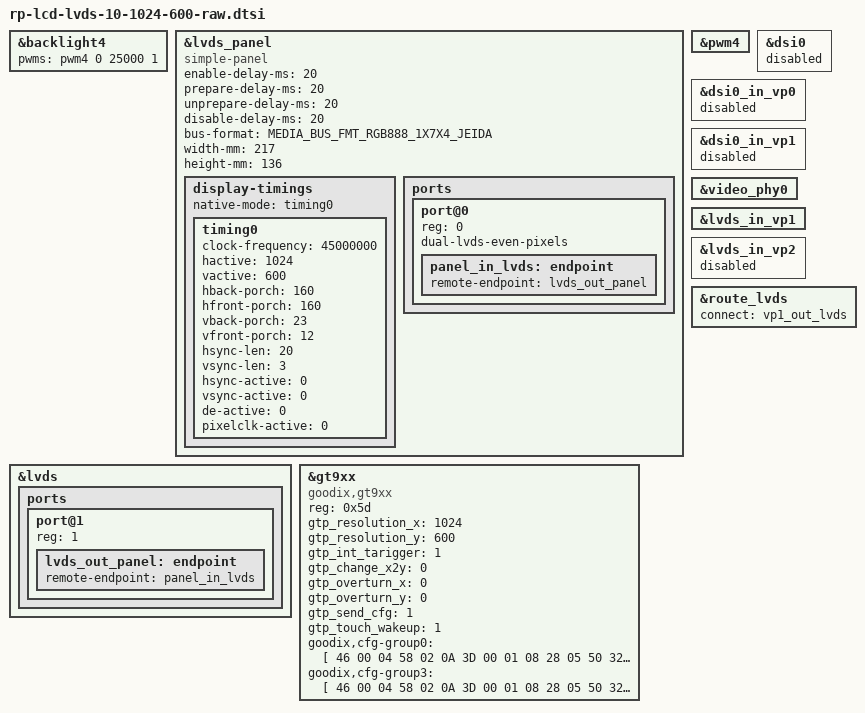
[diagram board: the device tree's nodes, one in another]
#include <dt-bindings/display/media-bus-format.h>
#include "rp-lcd-hdmi.dtsi"

&backlight4{
		pwms = <&pwm4 0 25000 1>;   /** pwm polarity of raw lvds screen is inverse */
};

&lvds_panel {
	status = "okay";
	compatible = "simple-panel";
	enable-delay-ms = <20>;
	prepare-delay-ms = <20>;
	unprepare-delay-ms = <20>;
	disable-delay-ms = <20>;
	bus-format = <MEDIA_BUS_FMT_RGB888_1X7X4_JEIDA>;
	width-mm = <217>;
	height-mm = <136>;
		
		/*
		 * power-supply = <>;
		 * reset-gpios = <>;
		 *
		 * lcd reset pin and power supply
		 * please refer to ***-lcd-gpio.dtsi
		 * that included in main dts.
		 */
		
	display-timings {
		native-mode = <&timing0>;

		timing0: timing0 {
			clock-frequency = <45000000>;
			hactive = <1024>;
			vactive = <600>;
			hback-porch = <160>;
			hfront-porch = <160>;
			vback-porch = <23>;
			vfront-porch = <12>;
			hsync-len = <20>;
			vsync-len = <3>;
			hsync-active = <0>;
			vsync-active = <0>;
			de-active = <0>;
			pixelclk-active = <0>;
		};
	};

	ports {
		#address-cells = <1>;
		#size-cells = <0>;

		port@0 {
			reg = <0>;
			dual-lvds-even-pixels;
			panel_in_lvds: endpoint {
				remote-endpoint = <&lvds_out_panel>;
			};
		};
	};
};

&lvds {
	status = "okay";
	ports {
		port@1 {
			reg = <1>;

			lvds_out_panel: endpoint {
				remote-endpoint = <&panel_in_lvds>;
			};
		};
	};
};





&pwm4 {
	status = "okay";
};

&dsi0 {
	status = "disabled";
};

&dsi0_in_vp0 {
	status = "disabled";
};

&dsi0_in_vp1 {
	status = "disabled";
};

&video_phy0 {
	status = "okay";
};

&lvds_in_vp1 {
	status = "okay";
};

&lvds_in_vp2 {
	status = "disabled";
};

&route_lvds {
	status = "okay";
	connect = <&vp1_out_lvds>;
};


	
&gt9xx {
        status = "okay";
        compatible = "goodix,gt9xx";
        reg = <0x5d>;
        gtp_resolution_x = <1024>;
        gtp_resolution_y = <600>;
        gtp_int_tarigger = <1>;
        gtp_change_x2y = <0>;
        gtp_overturn_x = <0>;
        gtp_overturn_y = <0>;
        gtp_send_cfg = <1>;
        gtp_touch_wakeup = <1>;

		/**
		 * goodix_rst_gpio = <>;
		 * goodix_irq_gpio = <>;
		 *
		 * touch panel interrupt and reset pin
		 * please refer to ***-lcd-gpio.dtsi
		 * that included in main dts.
		 */

        goodix,cfg-group0 = [
            46 00 04 58 02 0A 3D 00 01 08
            28 05 50 32 03 05 00 00 00 00
            00 00 00 18 1A 1E 14 8D 2D 88
            17 15 31 0D 00 00 01 9B 03 1D
            00 00 00 00 00 00 00 00 00 00
            00 1E 5A 94 C5 02 08 00 00 00
            61 21 00 57 29 00 4E 34 00 48
            41 00 43 51 00 43 00 00 00 00
            00 00 00 00 00 00 00 00 00 00
            00 00 00 00 00 00 00 00 00 00
            00 00 00 00 00 00 00 00 00 00
            00 00 00 01 04 05 06 07 08 09
            0C 0D 0E 0F 10 11 14 15 FF FF
            FF FF 00 00 00 00 00 00 00 00
            00 00 00 02 04 06 07 08 0A 0C
            0F 10 11 12 13 19 1B 1C 1E 1F
            20 21 22 23 24 25 26 27 FF FF
            FF FF FF FF 00 00 00 00 00 00
            00 00 00 00 FD 01];
        goodix,cfg-group3 = [
            46 00 04 58 02 0A 3D 00 01 08
            28 05 50 32 03 05 00 00 00 00
            00 00 00 18 1A 1E 14 8D 2D 88
            17 15 31 0D 00 00 01 9B 03 1D
            00 00 00 00 00 00 00 00 00 00
            00 1E 5A 94 C5 02 08 00 00 00
            61 21 00 57 29 00 4E 34 00 48
            41 00 43 51 00 43 00 00 00 00
            00 00 00 00 00 00 00 00 00 00
            00 00 00 00 00 00 00 00 00 00
            00 00 00 00 00 00 00 00 00 00
            00 00 00 01 04 05 06 07 08 09
            0C 0D 0E 0F 10 11 14 15 FF FF
            FF FF 00 00 00 00 00 00 00 00
            00 00 00 02 04 06 07 08 0A 0C
            0F 10 11 12 13 19 1B 1C 1E 1F
            20 21 22 23 24 25 26 27 FF FF
            FF FF FF FF 00 00 00 00 00 00
            00 00 00 00 FD 01];

};
